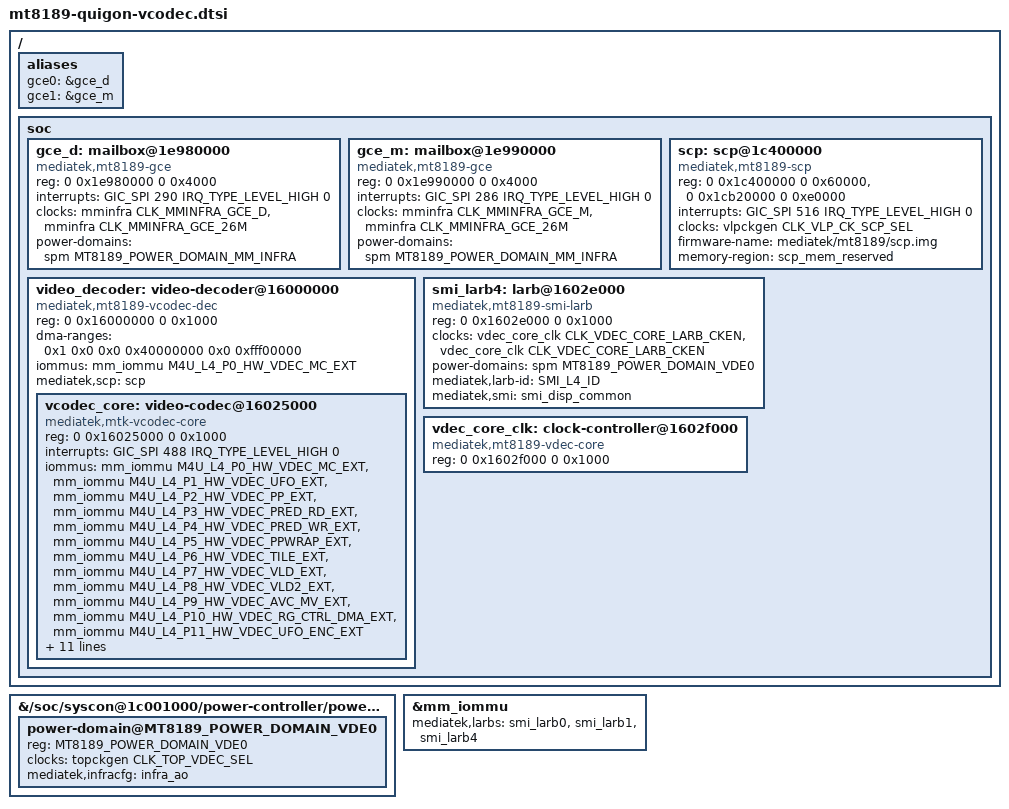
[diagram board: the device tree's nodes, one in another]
// SPDX-License-Identifier: (GPL-2.0 OR MIT)
/*
 * Hardware video decoding for quigon: the SCP (System Companion Processor, which runs the codec firmware
 * mediatek/mt8189/scp.img), the VDE0 power domain, the vdec clock controller, SMI larb4 and the stateless V4L2
 * decoder (MT8189 is "pure single core": one core block, no LAT). Nodes from ChromeOS's mt8189.dtsi and
 * mt8189-skywalker.dtsi; the decoder node follows mainline's MT8186 layout.
 *
 * Needs mt8189-quigon-display.dtsi (MM_INFRA power domain) and mt8189-quigon-iommu.dtsi (mm_iommu, smi_disp_common),
 * included before this file.
 */
#include <dt-bindings/memory/mediatek,mt8189-memory-port.h>

/ {
	aliases {
		/* mtk-cmdq-mailbox finds both GCEs by these to enable each one's clock */
		gce0 = &gce_d;
		gce1 = &gce_m;
	};

	soc {
		/*
		 * The two GCEs (command queue engines), from ChromeOS's mt8189.dtsi. The SCP firmware programs
		 * the video decoder through GCE command lists; the GCE driver turns on their DRAM access
		 * (GCE_GCTL_VALUE DDR_EN) and slot cycles at probe. Without them the media GCE can't fetch the
		 * firmware's commands and the decoder never completes a frame.
		 */
		gce_d: mailbox@1e980000 {
			compatible = "mediatek,mt8189-gce";
			reg = <0 0x1e980000 0 0x4000>;
			interrupts = <GIC_SPI 290 IRQ_TYPE_LEVEL_HIGH 0>;
			#mbox-cells = <2>;
			clocks = <&mminfra CLK_MMINFRA_GCE_D>, <&mminfra CLK_MMINFRA_GCE_26M>;
			clock-names = "gce0", "gce-timer";
			power-domains = <&spm MT8189_POWER_DOMAIN_MM_INFRA>;
		};

		gce_m: mailbox@1e990000 {
			compatible = "mediatek,mt8189-gce";
			reg = <0 0x1e990000 0 0x4000>;
			interrupts = <GIC_SPI 286 IRQ_TYPE_LEVEL_HIGH 0>;
			#mbox-cells = <2>;
			clocks = <&mminfra CLK_MMINFRA_GCE_M>, <&mminfra CLK_MMINFRA_GCE_26M>;
			clock-names = "gce1", "gce-timer";
			power-domains = <&spm MT8189_POWER_DOMAIN_MM_INFRA>;
		};

		scp: scp@1c400000 {
			compatible = "mediatek,mt8189-scp";
			reg = <0 0x1c400000 0 0x60000>,
			      <0 0x1cb20000 0 0xe0000>;
			reg-names = "sram", "cfg";
			interrupts = <GIC_SPI 516 IRQ_TYPE_LEVEL_HIGH 0>;
			clocks = <&vlpckgen CLK_VLP_CK_SCP_SEL>;
			clock-names = "main";
			firmware-name = "mediatek/mt8189/scp.img";
			memory-region = <&scp_mem_reserved>;
		};

		video_decoder: video-decoder@16000000 {
			compatible = "mediatek,mt8189-vcodec-dec";
			reg = <0 0x16000000 0 0x1000>;
			ranges;
			#address-cells = <2>;
			#size-cells = <2>;
			/* IOVA region 1 (4G-8G), the one mtk_iommu assigns to larb4 */
			dma-ranges = <0x1 0x0 0x0 0x40000000 0x0 0xfff00000>;
			iommus = <&mm_iommu M4U_L4_P0_HW_VDEC_MC_EXT>;
			mediatek,scp = <&scp>;

			vcodec_core: video-codec@16025000 {
				compatible = "mediatek,mtk-vcodec-core";
				reg = <0 0x16025000 0 0x1000>;
				interrupts = <GIC_SPI 488 IRQ_TYPE_LEVEL_HIGH 0>;
				iommus = <&mm_iommu M4U_L4_P0_HW_VDEC_MC_EXT>,
					 <&mm_iommu M4U_L4_P1_HW_VDEC_UFO_EXT>,
					 <&mm_iommu M4U_L4_P2_HW_VDEC_PP_EXT>,
					 <&mm_iommu M4U_L4_P3_HW_VDEC_PRED_RD_EXT>,
					 <&mm_iommu M4U_L4_P4_HW_VDEC_PRED_WR_EXT>,
					 <&mm_iommu M4U_L4_P5_HW_VDEC_PPWRAP_EXT>,
					 <&mm_iommu M4U_L4_P6_HW_VDEC_TILE_EXT>,
					 <&mm_iommu M4U_L4_P7_HW_VDEC_VLD_EXT>,
					 <&mm_iommu M4U_L4_P8_HW_VDEC_VLD2_EXT>,
					 <&mm_iommu M4U_L4_P9_HW_VDEC_AVC_MV_EXT>,
					 <&mm_iommu M4U_L4_P10_HW_VDEC_RG_CTRL_DMA_EXT>,
					 <&mm_iommu M4U_L4_P11_HW_VDEC_UFO_ENC_EXT>;
				/*
				 * The MMINFRA GCE gates: ChromeOS's mtk_mminfra driver keeps them on
				 * whenever MM_INFRA is powered; mainline has no such driver (and no GCE
				 * node), so the decoder holds them while it runs.
				 */
				clocks = <&topckgen CLK_TOP_VDEC_SEL>,
					 <&vdec_core_clk CLK_VDEC_CORE_VDEC_CKEN>,
					 <&vdec_core_clk CLK_VDEC_CORE_LARB_CKEN>,
					 <&topckgen CLK_TOP_UNIVPLL_D4>,
					 <&mminfra CLK_MMINFRA_GCE_D>,
					 <&mminfra CLK_MMINFRA_GCE_M>,
					 <&mminfra CLK_MMINFRA_GCE_26M>;
				clock-names = "vdec-sel", "vdec-soc-vdec", "vdec", "vdec-top",
					      "gce-d", "gce-m", "gce-26m";
				assigned-clocks = <&topckgen CLK_TOP_VDEC_SEL>;
				assigned-clock-parents = <&topckgen CLK_TOP_UNIVPLL_D4>;
				power-domains = <&spm MT8189_POWER_DOMAIN_VDE0>;
			};
		};

		smi_larb4: larb@1602e000 {
			compatible = "mediatek,mt8189-smi-larb";
			reg = <0 0x1602e000 0 0x1000>;
			clocks = <&vdec_core_clk CLK_VDEC_CORE_LARB_CKEN>,
				 <&vdec_core_clk CLK_VDEC_CORE_LARB_CKEN>;
			clock-names = "apb", "smi";
			power-domains = <&spm MT8189_POWER_DOMAIN_VDE0>;
			mediatek,larb-id = <SMI_L4_ID>;
			mediatek,smi = <&smi_disp_common>;
		};

		vdec_core_clk: clock-controller@1602f000 {
			compatible = "mediatek,mt8189-vdec-core";
			reg = <0 0x1602f000 0 0x1000>;
			/*
			 * The gates live in VDE0, but as on ChromeOS the provider has no power domain: its users power
			 * VDE0 first. Giving it one (runtime PM inside clk_prepare) wedged the clock framework.
			 */
			#clock-cells = <1>;
		};
	};
};

/*
 * VDE0 sits under MM_INFRA (ChromeOS scp_subdomain_mt8189_spm). Only the basic (topckgen) clock, as for DISP in
 * mt8189-quigon-display.dtsi: the vdec larb gate ChromeOS also lists ("vdec-0") lives in this very domain, and
 * mtk-pm-domains gets every domain's clocks at probe.
 */
&{/soc/syscon@1c001000/power-controller/power-domain@MT8189_POWER_DOMAIN_MM_INFRA} {
	power-domain@MT8189_POWER_DOMAIN_VDE0 {
		reg = <MT8189_POWER_DOMAIN_VDE0>;
		clocks = <&topckgen CLK_TOP_VDEC_SEL>;
		clock-names = "vdec";
		mediatek,infracfg = <&infra_ao>;
		#power-domain-cells = <0>;
	};
};

&mm_iommu {
	mediatek,larbs = <&smi_larb0 &smi_larb1 &smi_larb4>;
};
